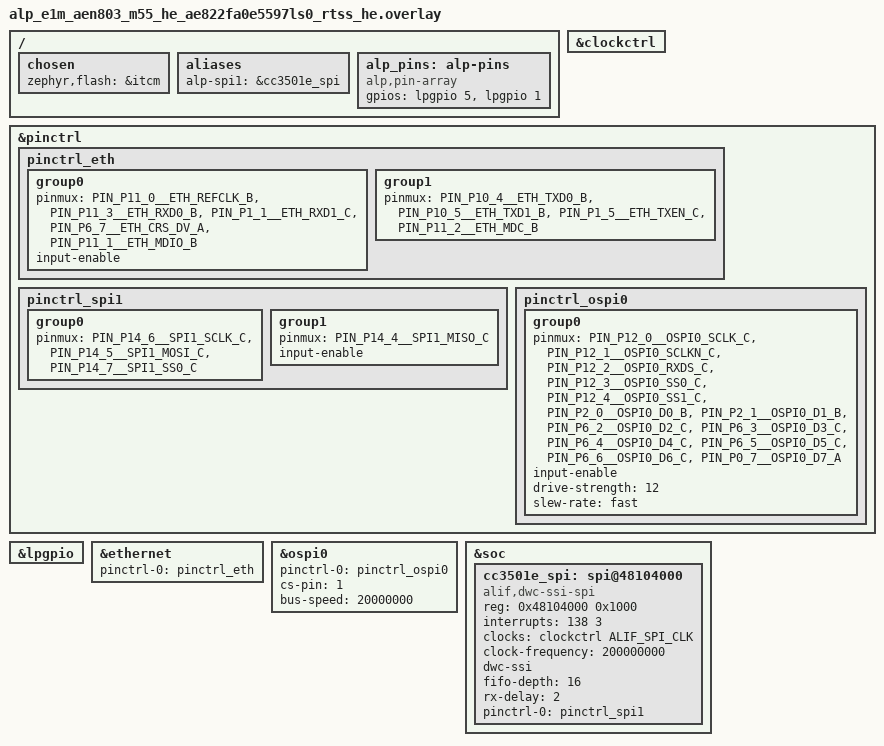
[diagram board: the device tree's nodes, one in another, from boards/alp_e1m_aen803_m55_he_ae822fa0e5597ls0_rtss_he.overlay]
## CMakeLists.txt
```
# SPDX-License-Identifier: Apache-2.0
#
# aen-power-domains -- bench RAM-run proof of the SoM power-domain runtime
# (#2784, unit U5) on the E1M-AEN803 (Alif Ensemble E8, M55-HE): quiesce every
# on-module domain, hold, restore, and check each chip answers again.
#
# Plain prj.conf app (no alp_project.py board.yaml flow); Zephyr applies
# boards/<fully-qualified-board>.overlay by itself.  Build with
#   ZEPHYR_BASE=<zephyr-base> west build \
#     -b alp_e1m_aen803_m55_he/ae822fa0e5597ls0/rtss_he <this-dir> -- \
#     "-DEXTRA_ZEPHYR_MODULES=<alp-sdk>;<hal_alif>"

cmake_minimum_required(VERSION 3.20)

find_package(Zephyr REQUIRED HINTS $ENV{ZEPHYR_BASE})
project(aen_power_domains LANGUAGES C)

# The quiesce / restore pair and the chip-hook binding are SDK-internal (the
# portable surface is only the three alp_power_domain_* / boot_wake_info calls),
# so this bench app reaches the internal header directly.
get_filename_component(ALP_SDK_ROOT ${CMAKE_CURRENT_SOURCE_DIR}/../../.. ABSOLUTE)
target_include_directories(app PRIVATE ${ALP_SDK_ROOT}/src/backends/power)

target_sources(app PRIVATE src/main.c)
# CC3501E bring-up template (cc3501e_bridge_bringup), same file the sibling
# aen-cc3501e-* examples carry.
target_sources(app PRIVATE src/cc3501e_bridge.c)
```

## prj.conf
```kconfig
# SPDX-License-Identifier: Apache-2.0
#
# Bench RAM-run config for the E1M-AEN803 (M55-HE).

CONFIG_ALP_SDK=y
CONFIG_ALP_SOC_ALIF_ENSEMBLE_E8=y

# <alp/power.h> domain API + the SoM power-domain runtime.  CONFIG_ALP_SDK_POWER
# is on by default; CONFIG_ALP_SDK_SOM_POWER follows from the generated
# alp,som-power node plus CONFIG_GPIO.  The Wi-Fi rail-off policy gate
# (CONFIG_ALP_SDK_SOM_PD_WIFI_RAIL_OFF) is deliberately NOT set: the example
# checks that RAIL_OFF is refused.
CONFIG_GPIO=y
CONFIG_PINCTRL=y

# CC3501E over the SPI1 inter-chip bridge.
CONFIG_SPI=y
CONFIG_ALP_SDK_CHIP_CC3501E=y

# TMP112 (BRD_I2C): read straight off the devicetree I2C address.
CONFIG_I2C=y

# External NOR (OSPI0 SS1) JEDEC ID.
CONFIG_FLASH=y
CONFIG_OSPI_ALIF=y
CONFIG_FLASH_JESD216_API=y

# Ethernet MAC: only for its MDIO block (the PHY ID / link check); same wiring
# as aen-ethernet-link.
CONFIG_NETWORKING=y
CONFIG_NET_L2_ETHERNET=y
CONFIG_ETH_DWMAC_ALIF=y
CONFIG_NET_IPV4=y
CONFIG_NET_IPV6=n
CONFIG_NET_UDP=y
CONFIG_NET_CONFIG_AUTO_INIT=n
CONFIG_NET_MGMT=y
CONFIG_NET_MGMT_EVENT=y
CONFIG_TEST_RANDOM_GENERATOR=y
CONFIG_NET_PKT_RX_COUNT=8
CONFIG_NET_PKT_TX_COUNT=8
CONFIG_NET_BUF_RX_COUNT=16
CONFIG_NET_BUF_TX_COUNT=16
CONFIG_DCACHE=n

CONFIG_MAIN_STACK_SIZE=4096
CONFIG_HEAP_MEM_POOL_SIZE=16384

# Console: Alp UART console -- E1M edge UART0 (Alif UART5, P3_4/P3_5, 115200
# 8N1, NS16550), the E1M-AEN carrier console.
CONFIG_SERIAL=y
CONFIG_CONSOLE=y
CONFIG_UART_CONSOLE=y
CONFIG_UART_INTERRUPT_DRIVEN=y
CONFIG_PRINTK=y
CONFIG_LOG=n
```

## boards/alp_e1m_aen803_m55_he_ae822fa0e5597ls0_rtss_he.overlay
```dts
/*
 * Copyright (c) 2026 Alp Lab AB
 * SPDX-License-Identifier: Apache-2.0
 *
 * aen-power-domains overlay for the E1M-AEN803 (Ensemble E8, M55-HE) RAM-run.
 *
 * Every domain the example round-trips needs its own bus up:
 *   - CC3501E : SPI1 (inter-chip bridge) + the WIFI_EN / nRESET LPGPIO pads;
 *   - PHY     : the GMAC (MDIO only) with its RMII pin group, GPIO11 (PHY reset);
 *   - NOR     : OSPI0, chip select 1;
 *   - TMP112  : BRD_I2C, already enabled by the board layer;
 *   - backlight : GPIO5 (P5_5).
 * The groups below are transcribed from the bench-proven siblings
 * aen-ethernet-link, aen-ospi-regcheck and aen-evk-demo; read their overlays for
 * the evidence behind each pad and value.
 */
#include <zephyr/dt-bindings/gpio/gpio.h>
#include <zephyr/dt-bindings/pinctrl/alif-ensemble-pinctrl.h>

/*
 * MANDATORY bench RAM-run retarget: run from ITCM so J-Link can loadbin+run
 * without programming MRAM, and drop the MCUboot code-partition fixup.
 */
/ {
	chosen {
		zephyr,flash = &itcm;
		/delete-property/ zephyr,code-partition;
	};

	aliases {
		/* bus_id 1 in alp_spi_open() -> the CC3501E bridge controller. */
		alp-spi1 = &cc3501e_spi;
	};

	/*
	 * The two SoM-internal CC3501E control nets, in the order
	 * cc3501e_bridge.h's CC3501E_BRIDGE_PIN_* indices expect.  Exactly ONE
	 * "alp,pin-array" node may exist in the tree.
	 */
	alp_pins: alp-pins {
		compatible = "alp,pin-array";
		gpios = <&lpgpio 5 GPIO_ACTIVE_HIGH>, /* [0] WIFI_EN     (P15_5)      */
			<&lpgpio 1 GPIO_ACTIVE_HIGH>; /* [1] E_WIFI.NRST (P15_1_FLEX) */
	};
};

&clockctrl {
	status = "okay";
};

&pinctrl {
	/* RMII to the DP83825 + MDIO: alif-ethernet-phy.tsv. */
	pinctrl_eth: pinctrl_eth {
		group0 {
			pinmux = <PIN_P11_0__ETH_REFCLK_B>, <PIN_P11_3__ETH_RXD0_B>,
				 <PIN_P1_1__ETH_RXD1_C>, <PIN_P6_7__ETH_CRS_DV_A>,
				 <PIN_P11_1__ETH_MDIO_B>;
			input-enable;
		};
		group1 {
			pinmux = <PIN_P10_4__ETH_TXD0_B>, <PIN_P10_5__ETH_TXD1_B>,
				 <PIN_P1_5__ETH_TXEN_C>, <PIN_P11_2__ETH_MDC_B>;
		};
	};

	/* SPI1 to the CC3501E; input-enable on MISO because the pad's input buffer is
	 * a PADCTRL bit that only pinctrl sets. */
	pinctrl_spi1: pinctrl_spi1 {
		group0 {
			pinmux = <PIN_P14_6__SPI1_SCLK_C>, <PIN_P14_5__SPI1_MOSI_C>,
				 <PIN_P14_7__SPI1_SS0_C>;
		};
		group1 {
			pinmux = <PIN_P14_4__SPI1_MISO_C>;
			input-enable;
		};
	};

	/* OSPI0 routing: alif-ospi.tsv (13 pads, all function 1). */
	pinctrl_ospi0: pinctrl_ospi0 {
		group0 {
			pinmux = <PIN_P12_0__OSPI0_SCLK_C>,
				 <PIN_P12_1__OSPI0_SCLKN_C>,
				 <PIN_P12_2__OSPI0_RXDS_C>,
				 <PIN_P12_3__OSPI0_SS0_C>,
				 <PIN_P12_4__OSPI0_SS1_C>,
				 <PIN_P2_0__OSPI0_D0_B>,
				 <PIN_P2_1__OSPI0_D1_B>,
				 <PIN_P6_2__OSPI0_D2_C>,
				 <PIN_P6_3__OSPI0_D3_C>,
				 <PIN_P6_4__OSPI0_D4_C>,
				 <PIN_P6_5__OSPI0_D5_C>,
				 <PIN_P6_6__OSPI0_D6_C>,
				 <PIN_P0_7__OSPI0_D7_A>;
			input-enable;
			drive-strength = <12>;
			slew-rate = "fast";
		};
	};
};

/* The pads the power layer drives: LPGPIO island (P15_n), GPIO11 (P11_6, PHY
 * reset), GPIO5 (P5_5, backlight); the stock board tree enables GPIO11 and GPIO5,
 * so only LPGPIO is enabled here.  Their mux and pad configuration come from
 * the pinctrl-0 state of the generated alp,som-power node, not from this app. */
&lpgpio {
	status = "okay";
};

&ethernet {
	pinctrl-0 = <&pinctrl_eth>;
	pinctrl-names = "default";
	status = "okay";
};

/*
 * cs-pin / bus-speed override the dtsi defaults: SS1 is where the fitted
 * IS25WX256-JHLE answers (SS0 is the HyperRAM footprint), at the 20 MHz the
 * #915 bench capture used.
 */
&ospi0 {
	status = "okay";
	pinctrl-0 = <&pinctrl_ospi0>;
	pinctrl-names = "default";
	cs-pin = <1>;
	bus-speed = <20000000>;
};

/*
 * DWC_ssi SPI1 -- the on-SoM CC3501E inter-chip link.  The consuming app
 * declares it (ensemble_e8_peripherals.dtsi only has the edge SPI0).
 * clock-frequency is REQUIRED (200 MHz SSI functional clock); rx-delay is
 * overwritten by the poke in src/cc3501e_bridge.c.  See aen-evk-demo's overlay
 * for the full argument and the unconfirmed SPI1 interrupt number.
 */
&soc {
	cc3501e_spi: spi@48104000 {
		compatible = "alif,dwc-ssi-spi";
		#address-cells = <1>;
		#size-cells = <0>;
		reg = <0x48104000 0x1000>;
		interrupts = <138 3>;          /* BENCH-TBD: confirm SPI1 IRQ */
		clocks = <&clockctrl ALIF_SPI_CLK>;
		clock-frequency = <200000000>;
		dwc-ssi;
		fifo-depth = <16>;
		rx-delay = <2>;
		pinctrl-0 = <&pinctrl_spi1>;
		pinctrl-names = "default";
		status = "okay";
	};
};
```

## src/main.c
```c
/*
 * Copyright 2026 Alp Lab AB
 * SPDX-License-Identifier: Apache-2.0
 *
 * aen-power-domains -- round-trip every quiesce-able on-module domain of the
 * E1M-AEN803 (Alif Ensemble E8, M55-HE) through the SoM power-domain runtime
 * (#2784, unit U5), RAM-run on the bench.
 *
 *
 * ==== WHAT THIS PROVES ==============================================
 *
 * Before STOP / STANDBY the SDK holds the on-module consumers that would
 * otherwise burn power through the sleep, and puts them back on the wake.  This
 * app runs that quiesce -> hold -> restore cycle in RUN mode (no STOP involved,
 * so no wake source and no cold boot), which isolates the half that has to work
 * before the STOP backend can rely on it: each chip must answer again after it
 * was held.
 *
 *   domain        quiesce (AUTO)                 comes back with
 *   -----------   ----------------------------   --------------------------------
 *   wifi_ble      E_WIFI_NRST (P15_1) held low   nRESET release = the
 *                                                cc3501e_hard_reset() semantics
 *   eth_phy       E_PHY_PWRDWN (P15_4) low       P15_4 high + E_PHY_RESET pulse
 *   ext_flash     OSPI1_RESETn (P15_7) low       release; driver told the part
 *                                                is back in 1-1-1 SPI
 *   ext_ram       OSPI0_RESETn (P15_6) low       release
 *   temp_sensor   TMP112 CONFIG.SD = 1           CONFIG.SD = 0
 *   rtc           CLKOUT low, EEPROM refresh     EEPROM refresh resumes; the RV-3028 was
 *                 paused (RV-3028 stays on)      never powered down
 *   backlight     BACKLIGHT_EN (P5_5) low        P5_5 back to its old level
 *
 * Two details worth knowing before reading the code:
 *
 *   - The CC3501E restore is NEVER cc3501e_reset().  That call drops WIFI_EN
 *     for 50 ms (a supply cold cycle), which on an activated module may never
 *     relaunch the firmware.  The SDK restore releases nRESET only, so the
 *     bench check "PING after restore, no WIFI_EN toggle" is the point of the
 *     CC3501E step.  The bring-up at the start follows the same rule: when
 *     WIFI_EN already reads high AND the chip answers a PING it resets through
 *     nRESET only; cc3501e_reset() runs only from WIFI_EN low or, as a last
 *     resort, from a chip that stays silent through an nRESET-only reset.
 *
 *   - The PHY's power state is tracked in SOFTWARE.  An unpowered DP83825 does
 *     not read back 0xFFFF over MDIO, it reads back stale data, so "the ID reads"
 *     is only meaningful after the restore, never as proof of the held state.
 *     E_PHY_PWRDWN is also the tri-state pin of the Y3 50 MHz reference
 *     oscillator, so the PHY clock stops and restarts with it.  The Ethernet
 *     interface is therefore taken down (net_if_down) before the quiesce and
 *     brought back up after the restore.
 *
 *
 * ==== BENCH CONTRACT ================================================
 *
 * Each step prints ONE stable line a bench script greps:
 *     POWER_DOMAINS: <step> <PASS|FAIL>
 * in this order:
 *     baseline_ping baseline_phy_id baseline_jedec baseline_temp
 *     rail_off_refused quiesce held_temp_sd held_ping_down
 *     restore ping_after phy_id_after phy_link_after jedec_after temp_after
 * and a final:
 *     POWER_DOMAINS: SUMMARY pass=<n> fail=<n>
 * Keep these strings byte-for-byte.
 */

#include <errno.h>
#include <stdbool.h>
#include <stdio.h>

#include <zephyr/device.h>
#include <zephyr/drivers/flash.h>
#include <zephyr/drivers/gpio.h>
#include <zephyr/drivers/i2c.h>
#include <zephyr/init.h>
#include <zephyr/kernel.h>
#include <zephyr/net/net_if.h>
#include <zephyr/sys/sys_io.h>
#include <zephyr/sys/util.h>

#include <alp/chips/cc3501e.h>
#include <alp/power.h>

#include "cc3501e_bridge.h" /* cc3501e_bridge_bringup() -- the SoM bring-up helper */
#include "som_power.h"      /* quiesce / restore pair (SDK-internal) */
#include "som_power_chips.h"

/* ---- Pads ------------------------------------------------------------------ */

/*
 * Power the PHY BEFORE the Ethernet driver's reference-clock probe looks for the
 * external 50 MHz oscillator, which is downstream of E_PHY_PWRDWN.  Same
 * sequence and priority as aen-ethernet-link (bench-verified): POST_KERNEL 50
 * sits after the GPIO controllers and before eth_dwmac (CONFIG_ETH_INIT_PRIORITY
 * 60).  Later, the power layer drives these same pads for the quiesce.
 */
static int phy_power_init(void)
{
	const struct device *gpio11 = DEVICE_DT_GET(DT_NODELABEL(gpio11));
	const struct device *lpgpio = DEVICE_DT_GET(DT_NODELABEL(lpgpio));

	if (!device_is_ready(gpio11) || !device_is_ready(lpgpio)) {
		return -ENODEV;
	}
	/* Mux and pad-configure every pad the power layer drives (P15_n, P11_6, P5_5)
	 * through the alp,som-power node's pinctrl-0 state -- the same state the layer
	 * applies itself before its first drive.  WIFI_EN / nRESET are covered by it
	 * too; cc3501e_bridge_bringup() still writes them by hand, harmlessly. */
	if (alp_som_power_pads_apply() != ALP_OK) {
		return -EIO;
	}

	(void)gpio_pin_configure(lpgpio, 4, GPIO_OUTPUT_ACTIVE); /* E_PHY_PWRDWN high = on */
	(void)gpio_pin_set(lpgpio, 4, 1);
	k_busy_wait(50000); /* supply + reference clock settle */
	(void)gpio_pin_configure(gpio11, 6, GPIO_OUTPUT_ACTIVE);
	(void)gpio_pin_set(gpio11, 6, 0); /* assert E_PHY_RESET */
	k_busy_wait(50000);
	(void)gpio_pin_set(gpio11, 6, 1); /* release */
	k_busy_wait(100000);              /* DP83825 post-reset settle */
	return 0;
}
SYS_INIT(phy_power_init, POST_KERNEL, 50);

/* ---- Step bookkeeping --------------------------------------------------------- */

static int g_pass;
static int g_fail;

static void step(const char *name, bool ok)
{
	printf("POWER_DOMAINS: %s %s\n", name, ok ? "PASS" : "FAIL");
	if (ok) {
		g_pass++;
	} else {
		g_fail++;
	}
}

/* ---- CC3501E ------------------------------------------------------------------- */

/* The inter-chip link needs a moment after a reset before it answers; poll by
 * repeating a zero-payload PING rather than stretching one timeout. */
#define PING_RETRIES 25
#define PING_GAP_MS  200

static cc3501e_t g_fw;

static bool ping_with_retry(void)
{
	for (int i = 0; i < PING_RETRIES; i++) {
		if (cc3501e_ping(&g_fw) == ALP_OK) {
			return true;
		}
		k_msleep(PING_GAP_MS);
	}
	return false;
}

/* ---- PHY (raw MDIO through the GMAC) -------------------------------------------- */

/*
 * MAC_MDIO_ADDRESS = GMAC base + 0x200: PA[25:21] PHY address, RDA[20:16]
 * register, CR[11:8] MDC divider, GOC bits 3..2 (read = both, write = bit 2),
 * GB bit 0 = busy; MAC_MDIO_DATA = base + 0x204.  Same access aen-ethernet-link
 * proved on this silicon.
 */
#define GMAC_MDIO_ADDR 0x48100200U
#define GMAC_MDIO_DATA 0x48100204U
#define PHY_ID_DP83825 0x2000a140U

/*
 * Bounded wait for GB (busy) to clear BEFORE issuing a transaction. Unbounded,
 * a GMAC whose clock was never enabled (net_if_up skipped or failed) holds GB
 * and hangs the caller before any result line prints. On timeout we fall
 * through and issue anyway; the post-issue wait is bounded too, and the read
 * then yields a non-PHY value that the scan/link checks report as a FAIL.
 */
static void mdio_wait_idle(void)
{
	for (int i = 0; i < 100000 && (sys_read32(GMAC_MDIO_ADDR) & BIT(0)) != 0U; i++) {
		k_busy_wait(1);
	}
}

static uint16_t mdio_read(uint8_t phy, uint8_t reg)
{
	mdio_wait_idle();
	sys_write32(((uint32_t)phy << 21) | ((uint32_t)reg << 16) | (0x4U << 8) | BIT(3) | BIT(2) |
	                BIT(0),
	            GMAC_MDIO_ADDR);
	for (int i = 0; i < 100000 && (sys_read32(GMAC_MDIO_ADDR) & BIT(0)) != 0U; i++) {
		k_busy_wait(1);
	}
	return (uint16_t)(sys_read32(GMAC_MDIO_DATA) & 0xFFFFU);
}

static void mdio_write(uint8_t phy, uint8_t reg, uint16_t val)
{
	mdio_wait_idle();
	sys_write32(val, GMAC_MDIO_DATA);
	sys_write32(((uint32_t)phy << 21) | ((uint32_t)reg << 16) | (0x4U << 8) | BIT(2) | BIT(0),
	            GMAC_MDIO_ADDR);
	for (int i = 0; i < 100000 && (sys_read32(GMAC_MDIO_ADDR) & BIT(0)) != 0U; i++) {
		k_busy_wait(1);
	}
}

/* Scan the 32 MDIO addresses for a responding PHY; returns its address or -1. */
static int phy_find(uint32_t *id_out)
{
	for (uint8_t phy = 0; phy < 32; phy++) {
		uint16_t id1 = mdio_read(phy, 2);
		if (id1 != 0xFFFFU && id1 != 0x0000U) {
			*id_out = ((uint32_t)id1 << 16) | mdio_read(phy, 3);
			return phy;
		}
	}
	return -1;
}

/*
 * A PHY that lost power also lost its strap-independent setting: select the
 * 50 MHz reference clock mode (RCSR bit 7) and restart auto-negotiation, then
 * wait for the wire link.  Same sequence as aen-ethernet-link's phy_wait_link().
 */
static bool phy_link_up(int phy)
{
	uint16_t rcsr = mdio_read((uint8_t)phy, 0x17);

	mdio_write((uint8_t)phy, 0x17, rcsr | BIT(7));
	mdio_write((uint8_t)phy, 0, BIT(12) | BIT(9)); /* BMCR: auto-neg enable + restart */
	for (int i = 0; i < 32; i++) {
		k_msleep(250);
		uint16_t bmsr = mdio_read((uint8_t)phy, 1);
		if ((bmsr & BIT(2)) != 0U && (bmsr & BIT(5)) != 0U) {
			return true;
		}
	}
	return false;
}

/* ---- NOR (OSPI0 SS1) ------------------------------------------------------------- */

#define NOR_JEDEC_IS25WX256_MFR 0x9dU /* ISSI; the fitted part answers 9d 5b 19 */

static bool nor_jedec_ok(uint8_t id[3])
{
	const struct device *ospi = DEVICE_DT_GET(DT_NODELABEL(ospi0));

	if (!device_is_ready(ospi)) {
		return false;
	}
	return flash_read_jedec_id(ospi, id) == 0 && id[0] == NOR_JEDEC_IS25WX256_MFR;
}

/* ---- TMP112 (BRD_I2C) -------------------------------------------------------------- */

#define TMP112_REG_TEMP 0x00U
#define TMP112_REG_CONF 0x01U
#define TMP112_CONF_SD  0x0100U

static const struct i2c_dt_spec tmp112 = I2C_DT_SPEC_GET(DT_NODELABEL(tmp112));

static bool tmp112_read16(uint8_t reg, uint16_t *out)
{
	uint8_t b[2];

	if (!device_is_ready(tmp112.bus) || i2c_burst_read_dt(&tmp112, reg, b, sizeof(b)) != 0) {
		return false;
	}
	*out = (uint16_t)(((uint16_t)b[0] << 8) | b[1]);
	return true;
}

/* 12-bit, left-justified, 0.0625 C/LSB; returns milli-degrees C. */
static bool tmp112_temp_milli_c(int32_t *out)
{
	uint16_t raw;

	if (!tmp112_read16(TMP112_REG_TEMP, &raw)) {
		return false;
	}
	*out = ((int32_t)(int16_t)raw >> 4) * 625 / 10;
	return true;
}

/* ---- Domain state table --------------------------------------------------------------- */

static const char *const domain_name[ALP_POWER_DOMAIN_COUNT] = {
	[ALP_POWER_DOMAIN_WIFI_BLE] = "wifi_ble",       [ALP_POWER_DOMAIN_ETH_PHY] = "eth_phy",
	[ALP_POWER_DOMAIN_EXT_FLASH] = "ext_flash",     [ALP_POWER_DOMAIN_EXT_RAM] = "ext_ram",
	[ALP_POWER_DOMAIN_TEMP_SENSOR] = "temp_sensor", [ALP_POWER_DOMAIN_RTC] = "rtc",
	[ALP_POWER_DOMAIN_BACKLIGHT] = "backlight",
};

static const char *state_name(alp_som_pd_state_t s)
{
	switch (s) {
	case ALP_SOM_PD_QUIESCED:
		return "QUIESCED";
	case ALP_SOM_PD_RESTORE_FAILED:
		return "RESTORE_FAILED";
	case ALP_SOM_PD_ACTIVE:
	default:
		return "ACTIVE";
	}
}

static void print_domains(const char *when)
{
	printf("domains %s:\n", when);
	for (int d = 0; d < (int)ALP_POWER_DOMAIN_COUNT; d++) {
		alp_power_domain_info_t info;

		if (alp_power_domain_info((alp_power_domain_t)d, &info) != ALP_OK || !info.present) {
			printf("  %-12s absent on this SKU\n", domain_name[d]);
			continue;
		}
		printf("  %-12s %-14s default_action=0x%02x holds_through_stop=%d dependents=0x%02x\n",
		       domain_name[d],
		       state_name(alp_som_power_state((alp_power_domain_t)d)),
		       (unsigned)info.default_action,
		       (int)info.holds_through_stop,
		       (unsigned)info.dependents);
	}
}

/* ---- Register snapshot (so acceptance needs no external probe) -------------------------- */

/* LPGPIO (DesignWare APB GPIO): SWPORTA_DR +0x00, SWPORTA_DDR +0x04, EXT_PORTA +0x50. */
#define LPGPIO_BASE DT_REG_ADDR(DT_NODELABEL(lpgpio))

static const struct i2c_dt_spec rv3028 = I2C_DT_SPEC_GET(DT_NODELABEL(rv3028));

#define RV3028_REG_SECONDS 0x00U
#define RV3028_REG_CTRL1   0x0FU
#define RV3028_REG_CLKOUT  0x35U

static void snapshot(const char *when)
{
	/* The pads the layer drives: P15_1 E_WIFI_NRST, P15_4 E_PHY_PWRDWN, P15_5
	 * WIFI_EN, P15_6 OSPI0_RESETn, P15_7 OSPI1_RESETn.  DR = the level written,
	 * DDR = 1 for an output, EXT = what the pad reads back (needs the pad's input
	 * buffer, which the pinctrl group enables). */
	uint32_t dr  = sys_read32(LPGPIO_BASE + 0x00U);
	uint32_t ddr = sys_read32(LPGPIO_BASE + 0x04U);
	uint32_t ext = sys_read32(LPGPIO_BASE + 0x50U);

	printf("snapshot %s: LPGPIO", when);
	static const int pads[] = { 1, 4, 5, 6, 7 };

	for (size_t i = 0; i < ARRAY_SIZE(pads); i++) {
		printf(" b%d(DR=%u DDR=%u EXT=%u)",
		       pads[i],
		       (unsigned)((dr >> pads[i]) & 1U),
		       (unsigned)((ddr >> pads[i]) & 1U),
		       (unsigned)((ext >> pads[i]) & 1U));
	}
	printf("\n");

	uint8_t t[3]  = { 0 };
	uint8_t ctrl1 = 0, clkout = 0;

	if (device_is_ready(rv3028.bus) && i2c_burst_read_dt(&rv3028, RV3028_REG_SECONDS, t, 3) == 0 &&
	    i2c_reg_read_byte_dt(&rv3028, RV3028_REG_CTRL1, &ctrl1) == 0 &&
	    i2c_reg_read_byte_dt(&rv3028, RV3028_REG_CLKOUT, &clkout) == 0) {
		printf("snapshot %s: RV-3028 time=%02x:%02x:%02x (BCD h:m:s) CTRL1=0x%02x "
		       "EE_CLKOUT=0x%02x\n",
		       when,
		       t[2] & 0x3FU,
		       t[1] & 0x7FU,
		       t[0] & 0x7FU,
		       ctrl1,
		       clkout);
	} else {
		printf("snapshot %s: RV-3028 read failed\n", when);
	}
}

#define HOLD_MS 5000

int main(void)
{
	printf("aen-power-domains: SoM power-domain quiesce/restore round trip (E1M-AEN803)\n");

	/* -- Bring-up (nRESET only when the chip is already powered; see the helper) ----- */
	alp_status_t br = cc3501e_bridge_bringup(&g_fw);

	printf("cc3501e_bridge_bringup -> %d\n", (int)br);

	struct net_if *iface = net_if_get_default();

	if (iface != NULL) {
		(void)net_if_up(iface); /* enables the GMAC clock the MDIO block needs */
	}
	k_msleep(500);

	/* Route the Wi-Fi/BLE domain through the CC3501E driver context so its own
	 * state (initialised) follows the quiesce.  The other domains use the
	 * devicetree pins / I2C address; the NOR hook binds itself at boot. */
	(void)alp_som_power_bind_cc3501e(&g_fw);

	/* -- Baseline ---------------------------------------------------------------------- */
	uint32_t phy_id = 0U;
	int      phy    = phy_find(&phy_id);
	uint8_t  jedec[3];
	int32_t  temp_mc = 0;

	step("baseline_ping", br == ALP_OK && ping_with_retry());
	step("baseline_phy_id", phy >= 0 && phy_id == PHY_ID_DP83825);
	step("baseline_jedec", nor_jedec_ok(jedec));
	step("baseline_temp", tmp112_temp_milli_c(&temp_mc));
	printf("baseline: phy@%d id=%08x jedec=%02x %02x %02x temp=%d mC\n",
	       phy,
	       (unsigned)phy_id,
	       jedec[0],
	       jedec[1],
	       jedec[2],
	       (int)temp_mc);

	/* -- Policy API ------------------------------------------------------------------- */
	alp_power_t *pw = alp_power_open();

	print_domains("before");
	snapshot("baseline");
	/* RAIL_OFF is opt-in behind CONFIG_ALP_SDK_SOM_PD_WIFI_RAIL_OFF, which this
	 * build leaves off: the request must be refused, and nothing changes. */
	alp_status_t ro = (pw != NULL) ? alp_power_domain_policy_set(pw,
	                                                             ALP_POWER_DOMAIN_WIFI_BLE,
	                                                             ALP_POWER_DOMAIN_POLICY_RAIL_OFF)
	                               : ALP_ERR_NOT_READY;

	step("rail_off_refused", ro == ALP_ERR_NOSUPPORT);

	/* -- Quiesce, hold ----------------------------------------------------------------- */
	/* Y3, the PHY's 50 MHz RMII reference oscillator, stops with the PHY: stop the
	 * MAC first so it does not run without its clock, and bring it back after. */
	if (iface != NULL) {
		(void)net_if_down(iface);
	}
	uint32_t     rollback_failed = 0U;
	alp_status_t q               = alp_som_power_quiesce(ALP_POWER_MODE_RUN, &rollback_failed);

	step("quiesce", q == ALP_OK && alp_som_power_quiesced() != 0U);
	print_domains("held");
	snapshot("hold");

	printf("holding %d ms (expect: PING down, TMP112 shutdown bit set, PHY clock stopped)\n",
	       HOLD_MS);
	k_msleep(HOLD_MS);

	uint16_t conf = 0U;

	step("held_temp_sd", tmp112_read16(TMP112_REG_CONF, &conf) && (conf & TMP112_CONF_SD) != 0U);
	/* The context is marked down while nRESET is low, so this fails at once
	 * instead of burning a full bridge timeout. */
	step("held_ping_down", cc3501e_ping(&g_fw) != ALP_OK);

	/* -- Restore ------------------------------------------------------------------------ */
	uint32_t     failed = 0U;
	alp_status_t r      = alp_som_power_restore(&failed);

	step("restore", r == ALP_OK && failed == 0U);
	if (iface != NULL) {
		(void)net_if_up(iface);
		k_msleep(500);
	}
	print_domains("after");
	snapshot("after");
	printf("restore: rc=%d failed_mask=0x%02x\n", (int)r, (unsigned)failed);

	/* -- Does each chip answer again? ------------------------------------------------------ */
	step("ping_after", ping_with_retry());

	phy = phy_find(&phy_id);
	step("phy_id_after", phy >= 0 && phy_id == PHY_ID_DP83825);
	step("phy_link_after", phy >= 0 && phy_link_up(phy));

	step("jedec_after", nor_jedec_ok(jedec));
	step("temp_after", tmp112_temp_milli_c(&temp_mc));
	printf("after: phy@%d id=%08x jedec=%02x %02x %02x temp=%d mC\n",
	       phy,
	       (unsigned)phy_id,
	       jedec[0],
	       jedec[1],
	       jedec[2],
	       (int)temp_mc);

	alp_power_close(pw);
	printf("POWER_DOMAINS: SUMMARY pass=%d fail=%d\n", g_pass, g_fail);
	return 0;
}
```

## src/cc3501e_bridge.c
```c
/*
 * SPDX-License-Identifier: Apache-2.0
 * Copyright 2026 Alp Lab AB
 *
 * E1M-AEN SoM CC3501E bridge bring-up helper -- see cc3501e_bridge.h.
 *
 * The final reset is warm-aware.  cc3501e_reset() drops WIFI_EN for 50 ms, a
 * supply cold cycle; on a CC3501E that is already running (an activated unit with
 * vendor_sbl_container_enable=1 may then never relaunch) that must not happen on a
 * mere re-run or warm reset of the application.  So when WIFI_EN already reads high
 * AND the chip answers a PING the bring-up resets through nRESET only
 * (cc3501e_hard_reset()), and uses cc3501e_reset() only from WIFI_EN low or, as a
 * last resort, from a chip that stays silent through an nRESET-only reset.  WIFI_EN
 * reading high alone is not trusted: a pull-up would make every power-on look warm
 * (whether the module has one is an open question, issue #2797).
 */

#include "cc3501e_bridge.h"

#if defined(CONFIG_SOC_AE822FA0E5597LS0_RTSS_HE) || defined(CONFIG_SOC_AE822FA0E5597LS0_RTSS_HP)
#include <zephyr/arch/cpu.h>
#include <zephyr/device.h>
#include <zephyr/drivers/gpio.h>
#include <zephyr/sys/sys_io.h>
/*
 * AEN LP-pad mux (Alif Ensemble E8, both M55-HE and M55-HP cores).  WIFI_EN
 * (P15_5) and nRESET (P15_1) are on the Alif LP-GPIO island, bound by the
 * generic snps,designware-gpio driver which does NOT apply Alif pinctrl --
 * so the LP pads stay un-muxed and their output drivers OFF (confirmed on
 * silicon on M55-HE: WIFI_EN never powers the CC3501E until these regs are
 * set).  0x23 = the Alif GPIO-output pad config (driver + read-enable +
 * drive strength).  TODO: drop this raw poke once the Alif GPIO backend
 * muxes the LP island via pinctrl.
 *
 * ALIF_LPGPIO_PADCTRL_BASE (0x42007000) is not an M55-HE-local address: the
 * shared upstream `pin-controller@1a603000` node (ensemble_common.dtsi,
 * included by both cores' SoC dtsi) declares this exact window as its
 * second `reg` range, and `alp_e1m_aen801_m55_hp-pinctrl.dtsi` already
 * muxes a different LP-GPIO pad (P15_0, RTC_ALARM) from the M55-HP pinctrl
 * driver through it, so the poke below is equally applicable on M55-HP.
 * Running it on M55-HP is NOT bench-proven -- only running it on M55-HE has
 * been confirmed on silicon.
 */
#define ALIF_LPGPIO_PADCTRL_BASE 0x42007000u
#define ALIF_PAD_GPIO_OUTPUT     0x23u
/* Latch WIFI_EN (P15_5) HIGH in the port's data register while the pad is still an
 * INPUT.  Switching the direction afterwards then drives the already-high level; the
 * other order (direction first, value second -- what gpio_dw's configure does even
 * with an init flag) drives whatever DR holds, and with DR bit 5 = 0 that glitches
 * the supply of a running chip low.  gpio_port_set_bits_raw() writes DR regardless
 * of direction. */
static void aen_wifi_en_latch_high(void)
{
	const struct device *lpgpio = DEVICE_DT_GET(DT_NODELABEL(lpgpio));

	if (device_is_ready(lpgpio)) {
		(void)gpio_port_set_bits_raw(lpgpio, BIT(5));
	}
}

static void aen_lp_pads_enable_output(void)
{
	sys_write32(ALIF_PAD_GPIO_OUTPUT, ALIF_LPGPIO_PADCTRL_BASE + 5u * 4u); /* P15_5 WIFI_EN */
	sys_write32(ALIF_PAD_GPIO_OUTPUT, ALIF_LPGPIO_PADCTRL_BASE + 1u * 4u); /* P15_1 nRESET  */
}
#else
static inline void aen_lp_pads_enable_output(void)
{
}
static inline void aen_wifi_en_latch_high(void)
{
}
#endif

alp_status_t cc3501e_bridge_bringup(cc3501e_t *fw)
{
	if (fw == NULL) {
		return ALP_ERR_INVAL;
	}

	/* 1. Control pins: WIFI_EN (supply gate) + nRESET.  These are Alif LP-GPIO
	 *    pads, not E1M edge pads -- the SoM owns them. */
	alp_gpio_t *wifi_en = alp_gpio_open(CC3501E_BRIDGE_PIN_WIFI_EN);
	alp_gpio_t *nrst    = alp_gpio_open(CC3501E_BRIDGE_PIN_NRST);
	if (wifi_en == NULL || nrst == NULL) {
		if (wifi_en != NULL) {
			alp_gpio_close(wifi_en);
		}
		if (nrst != NULL) {
			alp_gpio_close(nrst);
		}
		return ALP_ERR_NOT_PRESENT_ON_THIS_SOC;
	}
	aen_lp_pads_enable_output();
	/* Sample the supply gate BEFORE touching its direction.  High is only a HINT
	 * that the chip may be powered -- an external pull-up on WIFI_EN would make every
	 * power-on read high (whether the module has one is an OPEN QUESTION; the
	 * netlist has not been checked), so the decision below also needs a PING. */
	bool wifi_was_high = false;
	(void)alp_gpio_read(wifi_en, &wifi_was_high);
	if (wifi_was_high) {
		/* Latch the level in DR first so the direction change cannot glitch it low. */
		aen_wifi_en_latch_high();
	}
	(void)alp_gpio_configure(wifi_en, ALP_GPIO_OUTPUT, ALP_GPIO_PULL_NONE);
	(void)alp_gpio_configure(nrst, ALP_GPIO_OUTPUT, ALP_GPIO_PULL_NONE);

	/* 2. Inter-chip SPI (Alif = master).  CS is the dwc-ssi hardware SS0
	 *    muxed on P14_7; the app passes ALP_SPI_NO_CS so no software GPIO CS
	 *    is installed and the SPI controller drives SS0 per transfer.  Mode 0
	 *    matches the CC3501E vendor image frameFormat. */
	alp_spi_t *spi = alp_spi_open(&(alp_spi_config_t){
	    .bus_id        = CC3501E_BRIDGE_SPI_BUS_ID,
	    .freq_hz       = CC3501E_BRIDGE_SPI_FREQ_HZ,
	    .mode          = ALP_SPI_MODE_0,
	    .bits_per_word = 8u,
	    .cs_pin_id     = ALP_SPI_NO_CS,
	});
	if (spi == NULL) {
		alp_gpio_close(wifi_en);
		alp_gpio_close(nrst);
		return ALP_ERR_NOT_PRESENT_ON_THIS_SOC;
	}

#if CC3501E_BRIDGE_RX_SAMPLE_DLY > 0
	/* Raise the SCLK past 1 MHz: the DW SSI RX_SAMPLE_DLY register (0xf0) delays
	 * the MISO capture point by N ssi_clk cycles to cover the on-SoM trace + crossed
	 * data round-trip.  Zephyr spi_dw never writes it (leaves 0), so without this
	 * >1 MHz mis-samples MISO (cold reqhdr_rx=0xFFFFFFFF).  Written with SSI disabled
	 * (SSIENR=0); persists across the driver's per-transfer configure.  Value is
	 * silicon-tuned -- sweep CC3501E_BRIDGE_RX_SAMPLE_DLY at the target SCLK.
	 *
	 * SWEEP TRAP -- read before setting the constant to 0: the `#if > 0` above
	 * compiles this block out, so 0 does not mean "no delay", it means the SPI
	 * node's `rx-delay` devicetree value is left in place.  aen-cc3501e-bringup
	 * and aen-evk-demo declare rx-delay = <2>, so a naive N=0 sweep point on
	 * those two silently measures 2.  Read 0x481040F0 back to see what the link
	 * is actually running at. */
	{
		volatile uint32_t *ssienr =
		    (volatile uint32_t *)(uintptr_t)(CC3501E_BRIDGE_SPI1_BASE + 0x08u);
		volatile uint32_t *rsd = (volatile uint32_t *)(uintptr_t)(CC3501E_BRIDGE_SPI1_BASE + 0xf0u);
		uint32_t           en  = *ssienr;
		*ssienr                = 0u;
		*rsd                   = (uint32_t)CC3501E_BRIDGE_RX_SAMPLE_DLY;
		*ssienr                = en;
	}
#endif

	/* 3. Bind the bus + control pins; attach the GPIO proxy (proxied E1M IOs then
	 *    route over the bridge); run the power + reset sequence (TI SWRU626 + the
	 *    Puya cold-boot hard-reset workaround).  Leaves WIFI_EN HIGH. */
	(void)cc3501e_init(fw, spi);
	fw->enable_pin = wifi_en;
	fw->reset_pin  = nrst;
	/* READY (CC35 GPIO17) is NOT wired here by default on this R2 module --
	 * see chips/cc3501e/cc3501e_core.c's cc3501e_reply_gate() comment for the
	 * pin-routing fact, the bench evidence, and how a board that genuinely
	 * wires it can opt back in via fw->ready_pin. */
#ifdef CONFIG_ALP_SDK_GPIO_CC3501E_PROXY
	(void)alp_gpio_cc3501e_attach(fw);
#endif
#ifdef CONFIG_ALP_SDK_WIFI_CC3501E
	(void)alp_wifi_cc3501e_attach(fw);
#endif
#ifdef CONFIG_ALP_SDK_BLE_CC3501E
	(void)alp_ble_cc3501e_attach(fw);
#endif
	if (!wifi_was_high) {
		return cc3501e_reset(fw); /* supply low: the full cold-boot sequence */
	}
	/* WIFI_EN reads high.  Warm = the chip ANSWERS a PING; a pull-up alone proves
	 * nothing.  Warm: nRESET only, never a WIFI_EN toggle. */
	if (cc3501e_ping(fw) == ALP_OK) {
		return cc3501e_hard_reset(fw);
	}
	/* High but silent: powered-and-hung, or unpowered behind a pull-up.  Try the
	 * nRESET-only reset first (safe for a powered chip); only if the chip still does
	 * not answer is the supply cycled -- the last resort, taken from a chip that is
	 * already unresponsive. */
	if (cc3501e_hard_reset(fw) == ALP_OK && cc3501e_ping(fw) == ALP_OK) {
		return ALP_OK;
	}
	return cc3501e_reset(fw);
}
```
